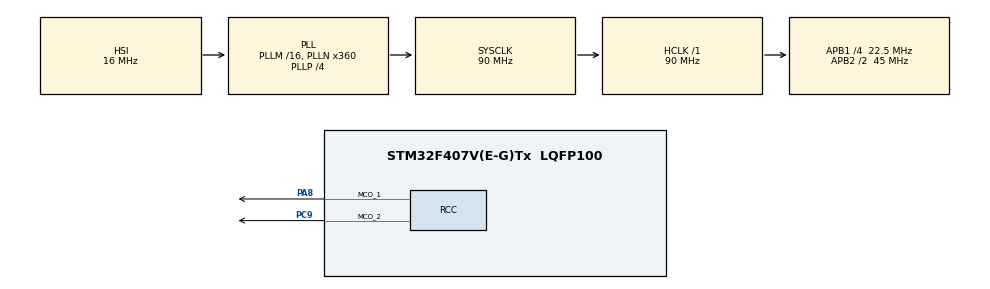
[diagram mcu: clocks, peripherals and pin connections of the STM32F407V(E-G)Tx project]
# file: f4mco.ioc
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Mcu.Family=STM32F4
Mcu.Name=STM32F407V(E-G)Tx
Mcu.Package=LQFP100
NVIC.PriorityGroup=NVIC_PRIORITYGROUP_4
PA8.GPIO_Speed=GPIO_SPEED_FREQ_VERY_HIGH
PA8.Mode=Clock-out-1
PA8.Signal=RCC_MCO_1
PC9.GPIO_Speed=GPIO_SPEED_FREQ_VERY_HIGH
PC9.Mode=Clock-out-2
PC9.Signal=RCC_MCO_2
ProjectManager.HeapSize=0x200
ProjectManager.StackSize=0x400
ProjectManager.TargetToolchain=EWARM V8
RCC.48MHZClocksFreq_Value=45000000
RCC.AHBFreq_Value=90000000
RCC.APB1CLKDivider=RCC_HCLK_DIV4
RCC.APB1Freq_Value=22500000
RCC.APB1TimFreq_Value=45000000
RCC.APB2CLKDivider=RCC_HCLK_DIV2
RCC.APB2Freq_Value=45000000
RCC.APB2TimFreq_Value=90000000
RCC.CortexFreq_Value=90000000
RCC.HCLKFreq_Value=90000000
RCC.HSE_VALUE=25000000
RCC.HSI_VALUE=16000000
RCC.LSE_VALUE=32768
RCC.PLLN=180
RCC.RCC_MCO1Source=RCC_MCO1SOURCE_PLLCLK
RCC.RCC_MCO2Source=RCC_MCO2SOURCE_PLLCLK
RCC.SYSCLKFreq_VALUE=90000000
RCC.SYSCLKSource=RCC_SYSCLKSOURCE_PLLCLK
RCC.VCOOutputFreq_Value=180000000
board=custom

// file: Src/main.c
/* USER CODE BEGIN Header */
/**
  ******************************************************************************
  * @file           : main.c
  * @brief          : Main program body
  ******************************************************************************
  * @attention
  *
  * <h2><center>&copy; Copyright (c) 2020 STMicroelectronics.
  * All rights reserved.</center></h2>
  *
  * This software component is licensed by ST under BSD 3-Clause license,
  * the "License"; You may not use this file except in compliance with the
  * License. You may obtain a copy of the License at:
  *                        opensource.org/licenses/BSD-3-Clause
  *
  ******************************************************************************
  */
/* USER CODE END Header */

#include "main.h"

void SystemClock_Config(void);
static void MX_GPIO_Init(void);

/* USER CODE BEGIN 0 */
volatile uint32_t Tone_enabled = 0;

void tone(int a,int freq,int d)
{
  uint32_t systick = 45000000 / freq;
  uint32_t len = d * freq / 500;
  SysTick->LOAD = systick;
  Tone_enabled = len;
  while (Tone_enabled);
  SysTick->LOAD = 45000;
}

#define delay HAL_Delay

void mario()
{
  tone(9,1318,150);
  delay(150);
  tone(9,1318,300);
  delay(300);
  tone(9,1318,150);
  delay(300);
  tone(9,1046,150);
  delay(150);
  tone(9,1318,300);
  delay(300);
  tone(9,1568,600);
  delay(600);
  tone(9,784,600);
  delay(600);
  tone(9,1046,450) ; // 2? ????
  delay(450);
  tone(9,784,150);
  delay(450);
  tone(9,659,300);
  delay(450);
  tone(9,880,300);
  delay(300);
  tone(9,987,150);
  delay(300);
  tone(9,932,150);
  delay(150);
  tone(9,880,300);
  delay(300);
  tone(9,784,210); // 3? ????
  delay(210);
  tone(9,1318,210);
  delay(210);
  tone(9,1568,150);
  delay(150);
  tone(9,1750,300);
  delay(300);
  tone(9,1396,150);
  delay(150);
  tone(9,1568,150);
  delay(300);
  tone(9,1318,300);
  delay(300);
  tone(9,1046,150);
  delay(150);
  tone(9,1174,150);
  delay(150);
  tone(9,987,450);
  delay(450);
  tone(9,1046,450); // 4? ????
  delay(450);
  tone(9,784,150);
  delay(450);
  tone(9,659,300);
  delay(450);
  tone(9,880,300);
  delay(300);
  tone(9,987,150);
  delay(300);
  tone(9,932,150);
  delay(150);
  tone(9,880,300);
  delay(300);
  tone(9,784,210); // 5? ????
  delay(210);
  tone(9,1318,210);
  delay(210);
  tone(9,1568,150);
  delay(150);
  tone(9,1750,300);
  delay(300);
  tone(9,1396,150);
  delay(150);
  tone(9,1568,150);
  delay(300);
  tone(9,1318,300);
  delay(300);
  tone(9,1046,150);
  delay(150);
  tone(9,1174,150);
  delay(150);
  tone(9,987,450);
  delay(600);
  tone(9,1568,150); // 6?? ????? ????
  delay(150);
  tone(9,1480,150);
  delay(150);
  tone(9,1396,150);
  delay(150);
  tone(9,1244,300);
  delay(300);
  tone(9,1318,150);
  delay(300);
  tone(9,830,150);
  delay(150);
  tone(9,880,150);
  delay(150);
  tone(9,1046,150);
  delay(300);
  tone(9,880,150);
  delay(150);
  tone(9,1046,150);
  delay(150);
  tone(9,1174,150);
  delay(150);
  delay(300); // 7??
  tone(9,1568,150);
  delay(150);
  tone(9,1480,150);
  delay(150);
  tone(9,1396,150);
  delay(150);
  tone(9,1244,300);
  delay(300);
  tone(9,1318,150);
  delay(300);
  tone(9,2093,300);
  delay(300);
  tone(9,2093,150);
  delay(150);
  tone(9,2093,600);
  delay(600);
  tone(9,1568,150); // 6?? ????? ???? ??????
  delay(150);
  tone(9,1480,150);
  delay(150);
  tone(9,1396,150);
  delay(150);
  tone(9,1244,300);
  delay(300);
  tone(9,1318,150);
  delay(300);
  tone(9,830,150);
  delay(150);
  tone(9,880,150);
  delay(150);
  tone(9,1046,150);
  delay(300);
  tone(9,880,150);
  delay(150);
  tone(9,1046,150);
  delay(150);
  tone(9,1174,150);
  delay(450);
  tone(9,1244,300);
  delay(450);
  tone(9,1174,450);
  delay(450);
  tone(9,1046,600);
  delay(1200 );
  tone(9,1568,150); // 6?? ????? ????
  delay(150);
  tone(9,1480,150);
  delay(150);
  tone(9,1396,150);
  delay(150);
  tone(9,1244,300);
  delay(300);
  tone(9,1318,150);
  delay(300);
  tone(9,830,150);
  delay(150);
  tone(9,880,150);
  delay(150);
  tone(9,1046,150);
  delay(300);
  tone(9,880,150);
  delay(150);
  tone(9,1046,150);
  delay(150);
  tone(9,1174,150);
  delay(150);
  delay(300); // 7??
  tone(9,1568,150);
  delay(150);
  tone(9,1480,150);
  delay(150);
  tone(9,1396,150);
  delay(150);
  tone(9,1244,300);
  delay(300);
  tone(9,1318,150);
  delay(300);
  tone(9,2093,300);
  delay(300);
  tone(9,2093,150);
  delay(150);
  tone(9,2093,600);
  delay(600);
  tone(9,1568,150); // 6?? ????? ???? ??????
  delay(150);
  tone(9,1480,150);
  delay(150);
  tone(9,1396,150);
  delay(150);
  tone(9,1244,300);
  delay(300);
  tone(9,1318,150);
  delay(300);
  tone(9,830,150);
  delay(150);
  tone(9,880,150);
  delay(150);
  tone(9,1046,150);
  delay(300);
  tone(9,880,150);
  delay(150);
  tone(9,1046,150);
  delay(150);
  tone(9,1174,150);
  delay(450);
  tone(9,1244,300);
  delay(450);
  tone(9,1174,450);
  delay(450);
  tone(9,1046,600);
  delay(1200);
  tone(9,1046,150); // 8?? ????
  delay(150);
  tone(9,1046,300);
  delay(300);
  tone(9,1046,150);
  delay(300);
  tone(9,1046,150);
  delay(150);
  tone(9,1174,300);
  delay(300);
  tone(9,1318,150);
  delay(150);
  tone(9,1046,300);
  delay(300);
  tone(9,880,150);
  delay(150);
  tone(9,784,600);
  delay(600);
  tone(9,1046,150);
  delay(150);
  tone(9,1046,300);
  delay(300);
  tone(9,1046,150);
  delay(300);
  tone(9,1046,150);
  delay(150);
  tone(9,1174,300);
  delay(300);
  tone(9,1318,150);
  delay(150);
  delay(1200);
  tone(9,1046,150); // 8?? ????
  delay(150);
  tone(9,1046,300);
  delay(300);
  tone(9,1046,150);
  delay(300);
  tone(9,1046,150);
  delay(150);
  tone(9,1174,300);
  delay(300);
  tone(9,1318,150);
  delay(150);
  tone(9,1046,300);
  delay(300);
  tone(9,880,150);
  delay(150);
  tone(9,784,600);
  delay(600);
  tone(9,1046,150);
  delay(150);
  tone(9,1046,300);
  delay(300);
  tone(9,1046,150);
  delay(300);
  tone(9,1046,150);
  delay(150);
  tone(9,1174,300);
  delay(300);
  tone(9,1318,150);
  delay(150);
  delay(1200);
  tone(9,1046,450) ; // 2? ????
  delay(450);
  tone(9,784,150);
  delay(450);
  tone(9,659,300);
  delay(450);
  tone(9,880,300);
  delay(300);
  tone(9,987,150);
  delay(300);
  tone(9,932,150);
  delay(150);
  tone(9,880,300);
  delay(300);
  tone(9,784,210); // 3? ????
  delay(210);
  tone(9,1318,210);
  delay(210);
  tone(9,1568,150);
  delay(150);
  tone(9,1750,300);
  delay(300);
  tone(9,1396,150);
  delay(150);
  tone(9,1568,150);
  delay(300);
  tone(9,1318,300);
  delay(300);
  tone(9,1046,150);
  delay(150);
  tone(9,1174,150);
  delay(150);
  tone(9,987,450);
  delay(450);
  tone(9,1046,450); // 4? ????
  delay(450);
  tone(9,784,150);
  delay(450);
  tone(9,659,300);
  delay(450);
  tone(9,880,300);
  delay(300);
  tone(9,987,150);
  delay(300);
  tone(9,932,150);
  delay(150);
  tone(9,880,300);
  delay(300);
  tone(9,784,210); // 5? ????
  delay(210);
  tone(9,1318,210);
  delay(210);
  tone(9,1568,150);
  delay(150);
  tone(9,1750,300);
  delay(300);
  tone(9,1396,150);
  delay(150);
  tone(9,1568,150);
  delay(300);
  tone(9,1318,300);
  delay(300);
  tone(9,1046,150);
  delay(150);
  tone(9,1174,150);
  delay(150);
  tone(9,987,450);
  delay(600);
  tone(9,1568,150); // 6?? ????? ????
  delay(150);
  tone(9,1480,150);
  delay(150);
  tone(9,1396,150);
  delay(150);
  tone(9,1244,300);
  delay(300);
  tone(9,1318,150);
  delay(300);
  tone(9,830,150);
  delay(150);
  tone(9,880,150);
  delay(150);
  tone(9,1046,150);
  delay(300);
  tone(9,880,150);
  delay(150);
  tone(9,1046,150);
  delay(150);
  tone(9,1174,150);
  delay(150);
  delay(300); // 7??
  tone(9,1568,150);
  delay(150);
  tone(9,1480,150);
  delay(150);
  tone(9,1396,150);
  delay(150);
  tone(9,1244,300);
  delay(300);
  tone(9,1318,150);
  delay(300);
  tone(9,2093,300);
  delay(300);
  tone(9,2093,150);
  delay(150);
  tone(9,2093,600);
  delay(600);
  tone(9,1568,150); // 6?? ????? ???? ??????
  delay(150);
  tone(9,1480,150);
  delay(150);
  tone(9,1396,150);
  delay(150);
  tone(9,1244,300);
  delay(300);
  tone(9,1318,150);
  delay(300);
  tone(9,830,150);
  delay(150);
  tone(9,880,150);
  delay(150);
  tone(9,1046,150);
  delay(300);
  tone(9,880,150);
  delay(150);
  tone(9,1046,150);
  delay(150);
  tone(9,1174,150);
  delay(450);
  tone(9,1244,300);
  delay(450);
  tone(9,1174,450);
  delay(450);
  tone(9,1046,600);
  delay(1200 );
  tone(9,1568,150); // 6?? ????? ????
  delay(150);
  tone(9,1480,150);
  delay(150);
  tone(9,1396,150);
  delay(150);
  tone(9,1244,300);
  delay(300);
  tone(9,1318,150);
  delay(300);
  tone(9,830,150);
  delay(150);
  tone(9,880,150);
  delay(150);
  tone(9,1046,150);
  delay(300);
  tone(9,880,150);
  delay(150);
  tone(9,1046,150);
  delay(150);
  tone(9,1174,150);
  delay(150);
  delay(300); // 7??
  tone(9,1568,150);
  delay(150);
  tone(9,1480,150);
  delay(150);
  tone(9,1396,150);
  delay(150);
  tone(9,1244,300);
  delay(300);
  tone(9,1318,150);
  delay(300);
  tone(9,2093,300);
  delay(300);
  tone(9,2093,150);
  delay(150);
  tone(9,2093,600);
  delay(600);
  tone(9,1568,150); // 6?? ????? ???? ??????
  delay(150);
  tone(9,1480,150);
  delay(150);
  tone(9,1396,150);
  delay(150);
  tone(9,1244,300);
  delay(300);
  tone(9,1318,150);
  delay(300);
  tone(9,830,150);
  delay(150);
  tone(9,880,150);
  delay(150);
  tone(9,1046,150);
  delay(300);
  tone(9,880,150);
  delay(150);
  tone(9,1046,150);
  delay(150);
  tone(9,1174,150);
  delay(450);
  tone(9,1244,300);
  delay(450);
  tone(9,1174,450);
  delay(450);
  tone(9,1046,600);
  delay(1200);
  tone(9,1046,150); // 8?? ????
  delay(150);
  tone(9,1046,300);
  delay(300);
  tone(9,1046,150);
  delay(300);
  tone(9,1046,150);
  delay(150);
  tone(9,1174,300);
  delay(300);
  tone(9,1318,150);
  delay(150);
  tone(9,1046,300);
  delay(300);
  tone(9,880,150);
  delay(150);
  tone(9,784,600);
  delay(600);
  tone(9,1046,150);
  delay(150);
  tone(9,1046,300);
  delay(300);
  tone(9,1046,150);
  delay(300);
  tone(9,1046,150);
  delay(150);
  tone(9,1174,300);
  delay(300);
  tone(9,1318,150);
  delay(150);
  delay(1200);
  tone(9,1046,150); // 8?? ????
  delay(150);
  tone(9,1046,300);
  delay(300);
  tone(9,1046,150);
  delay(300);
  tone(9,1046,150);
  delay(150);
  tone(9,1174,300);
  delay(300);
  tone(9,1318,150);
  delay(150);
  tone(9,1046,300);
  delay(300);
  tone(9,880,150);
  delay(150);
  tone(9,784,600);
  delay(600);
  tone(9,1046,150);
  delay(150);
  tone(9,1046,300);
  delay(300);
  tone(9,1046,150);
  delay(300);
  tone(9,784,150);
  delay(150);
  tone(9,1174,300);
  delay(300);
  tone(9,1046,2400);
  delay(2400);
  delay(1200);
}

void starwars()
{
tone(5, 392, 350);
delay(350);
tone(5, 392, 350);
delay(350);
tone(5, 392, 350);
delay(350);
tone(5, 311, 250);
delay(250);
tone(5, 466, 100);
delay(100);
tone(5, 392, 350);
delay(350);
tone(5, 311, 250);
delay(250);
tone(5, 466, 100);
delay(100);
tone(5, 392, 700);
delay(700);

tone(5, 587, 350);
delay(350);
tone(5, 587, 350);
delay(350);
tone(5, 587, 350);
delay(350);
tone(5, 622, 250);
delay(250);
tone(5, 466, 100);
delay(100);
tone(5, 369, 350);
delay(350);
tone(5, 311, 250);
delay(250);
tone(5, 466, 100);
delay(100);
tone(5, 392, 700);
delay(700);

tone(5, 784, 350);
delay(350);
tone(5, 392, 250);
delay(250);
tone(5, 392, 100);
delay(100);
tone(5, 784, 350);
delay(350);
tone(5, 739, 250);
delay(250);
tone(5, 698, 100);
delay(100);
tone(5, 659, 100);
delay(100);
tone(5, 622, 100);
delay(100);
tone(5, 659, 450);
delay(450);

tone(5, 415, 150);
delay(150);
tone(5, 554, 350);
delay(350);
tone(5, 523, 250);
delay(250);
tone(5, 493, 100);
delay(100);
tone(5, 466, 100);
delay(100);
tone(5, 440, 100);
delay(100);
tone(5, 466, 450);
delay(450);

tone(5, 311, 150);
delay(150);
tone(5, 369, 350);
delay(350);
tone(5, 311, 250);
delay(250);
tone(5, 466, 100);
delay(100);
tone(5, 392, 750);
delay(750);
delay(5000);

}
/* USER CODE END 0 */

int main(void)
{

  /* MCU Configuration--------------------------------------------------------*/

  /* Reset of all peripherals, Initializes the Flash interface and the Systick. */
  HAL_Init();

  /* Configure the system clock */
  SystemClock_Config();

  /* Initialize all configured peripherals */
  MX_GPIO_Init();
  /* USER CODE BEGIN 2 */
  /*
  SysTick->LOAD = 90;

  while(1);
  */
  /* USER CODE END 2 */

  /* Infinite loop */
  while (1)
  {
    //mario();
    starwars();
  }
}

void SystemClock_Config(void)
{
  RCC_OscInitTypeDef RCC_OscInitStruct = {0};
  RCC_ClkInitTypeDef RCC_ClkInitStruct = {0};

  /** Configure the main internal regulator output voltage
  */
  __HAL_RCC_PWR_CLK_ENABLE();
  __HAL_PWR_VOLTAGESCALING_CONFIG(PWR_REGULATOR_VOLTAGE_SCALE1);
  /** Initializes the CPU, AHB and APB busses clocks
  */
  RCC_OscInitStruct.OscillatorType = RCC_OSCILLATORTYPE_HSI;
  RCC_OscInitStruct.HSIState = RCC_HSI_ON;
  RCC_OscInitStruct.HSICalibrationValue = RCC_HSICALIBRATION_DEFAULT;
  RCC_OscInitStruct.PLL.PLLState = RCC_PLL_ON;
  RCC_OscInitStruct.PLL.PLLSource = RCC_PLLSOURCE_HSI;
  RCC_OscInitStruct.PLL.PLLM = 16;
  RCC_OscInitStruct.PLL.PLLN = 360;
  RCC_OscInitStruct.PLL.PLLP = RCC_PLLP_DIV4;
  RCC_OscInitStruct.PLL.PLLQ = 4;
  if (HAL_RCC_OscConfig(&RCC_OscInitStruct) != HAL_OK)
  {
    Error_Handler();
  }
  /** Initializes the CPU, AHB and APB busses clocks
  */
  RCC_ClkInitStruct.ClockType = RCC_CLOCKTYPE_HCLK|RCC_CLOCKTYPE_SYSCLK
                              |RCC_CLOCKTYPE_PCLK1|RCC_CLOCKTYPE_PCLK2;
  RCC_ClkInitStruct.SYSCLKSource = RCC_SYSCLKSOURCE_PLLCLK;
  RCC_ClkInitStruct.AHBCLKDivider = RCC_SYSCLK_DIV1;
  RCC_ClkInitStruct.APB1CLKDivider = RCC_HCLK_DIV4;
  RCC_ClkInitStruct.APB2CLKDivider = RCC_HCLK_DIV2;

  if (HAL_RCC_ClockConfig(&RCC_ClkInitStruct, FLASH_LATENCY_2) != HAL_OK)
  {
    Error_Handler();
  }
  HAL_RCC_MCOConfig(RCC_MCO1, RCC_MCO1SOURCE_PLLCLK, RCC_MCODIV_1);
  HAL_RCC_MCOConfig(RCC_MCO2, RCC_MCO2SOURCE_PLLCLK, RCC_MCODIV_1);
}

static void MX_GPIO_Init(void)
{
  GPIO_InitTypeDef GPIO_InitStruct = {0};

  /* GPIO Ports Clock Enable */
  __HAL_RCC_GPIOC_CLK_ENABLE();
  __HAL_RCC_GPIOA_CLK_ENABLE();

  /*Configure GPIO pin : PC9 */
  GPIO_InitStruct.Pin = GPIO_PIN_9;
  GPIO_InitStruct.Mode = GPIO_MODE_AF_PP;
  GPIO_InitStruct.Pull = GPIO_NOPULL;
  GPIO_InitStruct.Speed = GPIO_SPEED_FREQ_VERY_HIGH;
  GPIO_InitStruct.Alternate = GPIO_AF0_MCO;
  HAL_GPIO_Init(GPIOC, &GPIO_InitStruct);

  /*Configure GPIO pin : PA8 */
  GPIO_InitStruct.Pin = GPIO_PIN_8;
  GPIO_InitStruct.Mode = GPIO_MODE_AF_PP;
  GPIO_InitStruct.Pull = GPIO_NOPULL;
  GPIO_InitStruct.Speed = GPIO_SPEED_FREQ_VERY_HIGH;
  GPIO_InitStruct.Alternate = GPIO_AF0_MCO;
  HAL_GPIO_Init(GPIOA, &GPIO_InitStruct);

}

void Error_Handler(void)
{
}

/************************ (C) COPYRIGHT STMicroelectronics *****END OF FILE****/
